# CY8C5888LTI_LP097 register map
File version: 0.1
Registers are 8-bit, read-write, no defined reset value unless marked. A register's access mark holds for its fields unless they carry their own. Offsets are from the block's base; [hi:lo] are bit positions; 'fields as' and 'values as' point back to an identical list.

## Timer4
Base 0x00000000
0x40006506 Timer4_COUNTER 16-bit — UDB.A0 - Current Down Counter Value
0x40006526 Timer4_PERIOD 16-bit — UDB.D0 - Assigned Period
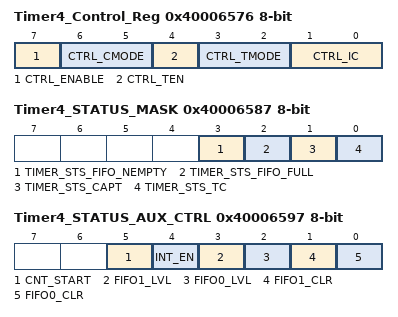
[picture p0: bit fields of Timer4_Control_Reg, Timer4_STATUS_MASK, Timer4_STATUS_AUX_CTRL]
0x40006576 Timer4_Control_Reg — UDB Control Register - Assigned Control Register Value
  [7] CTRL_ENABLE — Enable the Timer
  [6:5] CTRL_CMODE — Capture Mode
  [4] CTRL_TEN — Trigger Enable Bit
  [3:2] CTRL_TMODE — Trigger Mode
  [1:0] CTRL_IC — Interrupt Count
0x40006587 Timer4_STATUS_MASK — UDB Status bits Interrupt Mask Enable Register
  [3] TIMER_STS_FIFO_NEMPTY ro — FIFO Empty status
  [2] TIMER_STS_FIFO_FULL ro — FIFO Full Status
  [1] TIMER_STS_CAPT ro — Enables the Interrupt on Capture
  [0] TIMER_STS_TC ro — Enables the Interrupt on TC
0x40006597 Timer4_STATUS_AUX_CTRL — UDB Auxilliary Control Register
  [5] CNT_START — FIFO0 clear
    0=E_CNT_START0 (Disable counter); 1=E_CNT_START1 (Enable counter)
  [4] INT_EN
    0=E_INT_EN0 (Interrupt disabled); 1=E_INT_EN1 (Interrupt enabled)
  [3] FIFO1_LVL — FIFO level
    0=E_FIFO_LVL_0 (FIFO LVL: input mode: FIFO not full; output mode: FIFO not empty); 1=E_FIFO_LVL_1 (FIFO LVL: input mode: FIFO at least 1/2 empty; output mode: FIFO at least 1/2 full)
  [2] FIFO0_LVL — FIFO level
    values as FIFO1_LVL
  [1] FIFO1_CLR — FIFO1 clear
    0=E_FIFO_CLR_0 (Normal FIFO operation); 1=E_FIFO_CLR_1 (Clear FIFO state)
  [0] FIFO0_CLR — FIFO0 clear
    values as FIFO1_CLR

## Timer5
Base 0x00000000
0x4000650A Timer5_COUNTER 16-bit — UDB.A0 - Current Down Counter Value
0x4000652A Timer5_PERIOD 16-bit — UDB.D0 - Assigned Period
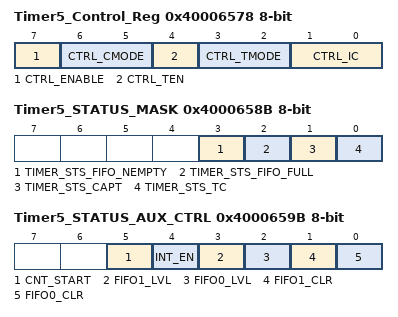
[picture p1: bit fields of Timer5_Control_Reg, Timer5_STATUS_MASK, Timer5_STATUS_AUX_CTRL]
0x40006578 Timer5_Control_Reg — UDB Control Register - Assigned Control Register Value
  [7] CTRL_ENABLE — Enable the Timer
  [6:5] CTRL_CMODE — Capture Mode
  [4] CTRL_TEN — Trigger Enable Bit
  [3:2] CTRL_TMODE — Trigger Mode
  [1:0] CTRL_IC — Interrupt Count
0x4000658B Timer5_STATUS_MASK — UDB Status bits Interrupt Mask Enable Register
  [3] TIMER_STS_FIFO_NEMPTY ro — FIFO Empty status
  [2] TIMER_STS_FIFO_FULL ro — FIFO Full Status
  [1] TIMER_STS_CAPT ro — Enables the Interrupt on Capture
  [0] TIMER_STS_TC ro — Enables the Interrupt on TC
0x4000659B Timer5_STATUS_AUX_CTRL — UDB Auxilliary Control Register
  [5] CNT_START — FIFO0 clear
    0=E_CNT_START0 (Disable counter); 1=E_CNT_START1 (Enable counter)
  [4] INT_EN
    0=E_INT_EN0 (Interrupt disabled); 1=E_INT_EN1 (Interrupt enabled)
  [3] FIFO1_LVL — FIFO level
    0=E_FIFO_LVL_0 (FIFO LVL: input mode: FIFO not full; output mode: FIFO not empty); 1=E_FIFO_LVL_1 (FIFO LVL: input mode: FIFO at least 1/2 empty; output mode: FIFO at least 1/2 full)
  [2] FIFO0_LVL — FIFO level
    values as FIFO1_LVL
  [1] FIFO1_CLR — FIFO1 clear
    0=E_FIFO_CLR_0 (Normal FIFO operation); 1=E_FIFO_CLR_1 (Clear FIFO state)
  [0] FIFO0_CLR — FIFO0 clear
    values as FIFO1_CLR

## Timer1
Base 0x00000000
0x40006402 Timer1_COUNTER 16-bit — UDB.A0 - Current Down Counter Value
0x40006422 Timer1_PERIOD 16-bit — UDB.D0 - Assigned Period
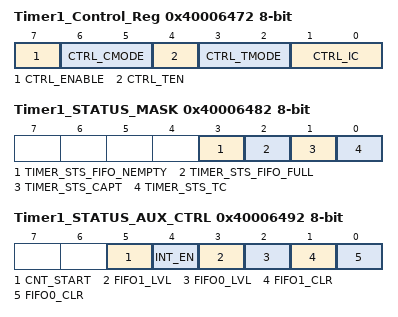
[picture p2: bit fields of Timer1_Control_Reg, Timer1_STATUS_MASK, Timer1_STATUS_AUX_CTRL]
0x40006472 Timer1_Control_Reg — UDB Control Register - Assigned Control Register Value
  [7] CTRL_ENABLE — Enable the Timer
  [6:5] CTRL_CMODE — Capture Mode
  [4] CTRL_TEN — Trigger Enable Bit
  [3:2] CTRL_TMODE — Trigger Mode
  [1:0] CTRL_IC — Interrupt Count
0x40006482 Timer1_STATUS_MASK — UDB Status bits Interrupt Mask Enable Register
  [3] TIMER_STS_FIFO_NEMPTY ro — FIFO Empty status
  [2] TIMER_STS_FIFO_FULL ro — FIFO Full Status
  [1] TIMER_STS_CAPT ro — Enables the Interrupt on Capture
  [0] TIMER_STS_TC ro — Enables the Interrupt on TC
0x40006492 Timer1_STATUS_AUX_CTRL — UDB Auxilliary Control Register
  [5] CNT_START — FIFO0 clear
    0=E_CNT_START0 (Disable counter); 1=E_CNT_START1 (Enable counter)
  [4] INT_EN
    0=E_INT_EN0 (Interrupt disabled); 1=E_INT_EN1 (Interrupt enabled)
  [3] FIFO1_LVL — FIFO level
    0=E_FIFO_LVL_0 (FIFO LVL: input mode: FIFO not full; output mode: FIFO not empty); 1=E_FIFO_LVL_1 (FIFO LVL: input mode: FIFO at least 1/2 empty; output mode: FIFO at least 1/2 full)
  [2] FIFO0_LVL — FIFO level
    values as FIFO1_LVL
  [1] FIFO1_CLR — FIFO1 clear
    0=E_FIFO_CLR_0 (Normal FIFO operation); 1=E_FIFO_CLR_1 (Clear FIFO state)
  [0] FIFO0_CLR — FIFO0 clear
    values as FIFO1_CLR

## Timer3
Base 0x00000000
0x40006406 Timer3_COUNTER 16-bit — UDB.A0 - Current Down Counter Value
0x40006426 Timer3_PERIOD 16-bit — UDB.D0 - Assigned Period
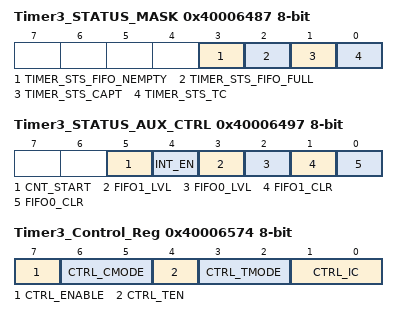
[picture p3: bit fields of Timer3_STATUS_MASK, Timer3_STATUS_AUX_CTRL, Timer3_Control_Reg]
0x40006487 Timer3_STATUS_MASK — UDB Status bits Interrupt Mask Enable Register
  [3] TIMER_STS_FIFO_NEMPTY ro — FIFO Empty status
  [2] TIMER_STS_FIFO_FULL ro — FIFO Full Status
  [1] TIMER_STS_CAPT ro — Enables the Interrupt on Capture
  [0] TIMER_STS_TC ro — Enables the Interrupt on TC
0x40006497 Timer3_STATUS_AUX_CTRL — UDB Auxilliary Control Register
  [5] CNT_START — FIFO0 clear
    0=E_CNT_START0 (Disable counter); 1=E_CNT_START1 (Enable counter)
  [4] INT_EN
    0=E_INT_EN0 (Interrupt disabled); 1=E_INT_EN1 (Interrupt enabled)
  [3] FIFO1_LVL — FIFO level
    0=E_FIFO_LVL_0 (FIFO LVL: input mode: FIFO not full; output mode: FIFO not empty); 1=E_FIFO_LVL_1 (FIFO LVL: input mode: FIFO at least 1/2 empty; output mode: FIFO at least 1/2 full)
  [2] FIFO0_LVL — FIFO level
    values as FIFO1_LVL
  [1] FIFO1_CLR — FIFO1 clear
    0=E_FIFO_CLR_0 (Normal FIFO operation); 1=E_FIFO_CLR_1 (Clear FIFO state)
  [0] FIFO0_CLR — FIFO0 clear
    values as FIFO1_CLR
0x40006574 Timer3_Control_Reg — UDB Control Register - Assigned Control Register Value
  [7] CTRL_ENABLE — Enable the Timer
  [6:5] CTRL_CMODE — Capture Mode
  [4] CTRL_TEN — Trigger Enable Bit
  [3:2] CTRL_TMODE — Trigger Mode
  [1:0] CTRL_IC — Interrupt Count

## Timer2
Base 0x00000000
0x40006504 Timer2_COUNTER 16-bit — UDB.A0 - Current Down Counter Value
0x40006524 Timer2_PERIOD 16-bit — UDB.D0 - Assigned Period
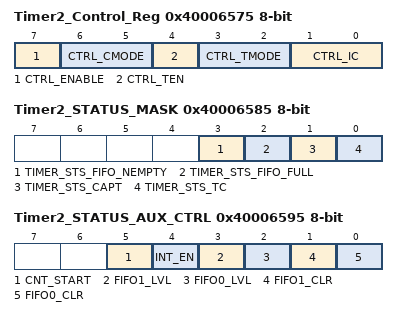
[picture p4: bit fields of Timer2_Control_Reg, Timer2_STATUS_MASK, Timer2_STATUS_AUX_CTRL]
0x40006575 Timer2_Control_Reg — UDB Control Register - Assigned Control Register Value
  [7] CTRL_ENABLE — Enable the Timer
  [6:5] CTRL_CMODE — Capture Mode
  [4] CTRL_TEN — Trigger Enable Bit
  [3:2] CTRL_TMODE — Trigger Mode
  [1:0] CTRL_IC — Interrupt Count
0x40006585 Timer2_STATUS_MASK — UDB Status bits Interrupt Mask Enable Register
  [3] TIMER_STS_FIFO_NEMPTY ro — FIFO Empty status
  [2] TIMER_STS_FIFO_FULL ro — FIFO Full Status
  [1] TIMER_STS_CAPT ro — Enables the Interrupt on Capture
  [0] TIMER_STS_TC ro — Enables the Interrupt on TC
0x40006595 Timer2_STATUS_AUX_CTRL — UDB Auxilliary Control Register
  [5] CNT_START — FIFO0 clear
    0=E_CNT_START0 (Disable counter); 1=E_CNT_START1 (Enable counter)
  [4] INT_EN
    0=E_INT_EN0 (Interrupt disabled); 1=E_INT_EN1 (Interrupt enabled)
  [3] FIFO1_LVL — FIFO level
    0=E_FIFO_LVL_0 (FIFO LVL: input mode: FIFO not full; output mode: FIFO not empty); 1=E_FIFO_LVL_1 (FIFO LVL: input mode: FIFO at least 1/2 empty; output mode: FIFO at least 1/2 full)
  [2] FIFO0_LVL — FIFO level
    values as FIFO1_LVL
  [1] FIFO1_CLR — FIFO1 clear
    0=E_FIFO_CLR_0 (Normal FIFO operation); 1=E_FIFO_CLR_1 (Clear FIFO state)
  [0] FIFO0_CLR — FIFO0 clear
    values as FIFO1_CLR

## UART_1 — UART
Base 0x00000000
0x4000644B TX_UART_1_TX_DATA — TX Data Register
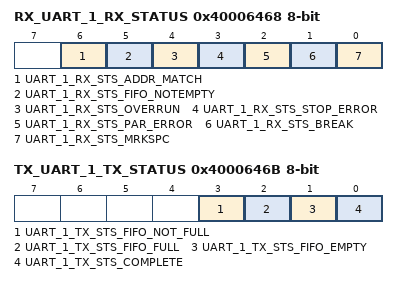
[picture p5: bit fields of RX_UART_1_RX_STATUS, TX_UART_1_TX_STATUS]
0x40006468 RX_UART_1_RX_STATUS — RX status register
  [6] UART_1_RX_STS_ADDR_MATCH ro, [5] UART_1_RX_STS_FIFO_NOTEMPTY ro, [4] UART_1_RX_STS_OVERRUN ro, [3] UART_1_RX_STS_STOP_ERROR ro, [2] UART_1_RX_STS_PAR_ERROR ro, [1] UART_1_RX_STS_BREAK ro, [0] UART_1_RX_STS_MRKSPC ro
0x4000646B TX_UART_1_TX_STATUS — TX status register
  [3] UART_1_TX_STS_FIFO_NOT_FULL ro, [2] UART_1_TX_STS_FIFO_FULL ro, [1] UART_1_TX_STS_FIFO_EMPTY ro, [0] UART_1_TX_STS_COMPLETE ro
0x40006529 RX_UART_1_RX_ADDRESS1 — RX Address1 Register
0x40006539 RX_UART_1_RX_ADDRESS2 — RX Address2 Register
0x40006549 RX_UART_1_RX_DATA — RX Data Register
